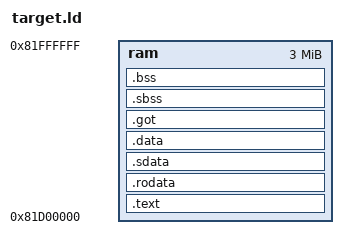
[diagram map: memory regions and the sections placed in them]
OUTPUT_ARCH(mips)
ENTRY(_start)
MEMORY
{
	ram	: ORIGIN = 0x82000000 - 0x300000 , LENGTH = 3M
}

SECTIONS
{
	. = ALIGN(4);
	.text : { *(.text*) } > ram

	. = ALIGN(4);
	.rodata : { *(.rodata*) } > ram

	. = ALIGN(4);
	.sdata : { *(.sdata*) } > ram

	. = ALIGN(4);
	.data : { *(.data*) *(.scommon*) *(.reginfo*) } > ram

	_gp = ALIGN(16);
	.got : { *(.got*) } > ram

	. = ALIGN(4);
	.sbss : { *(.sbss*) } > ram
	.bss : { *(.bss*) } > ram
	. = ALIGN (4);
}

